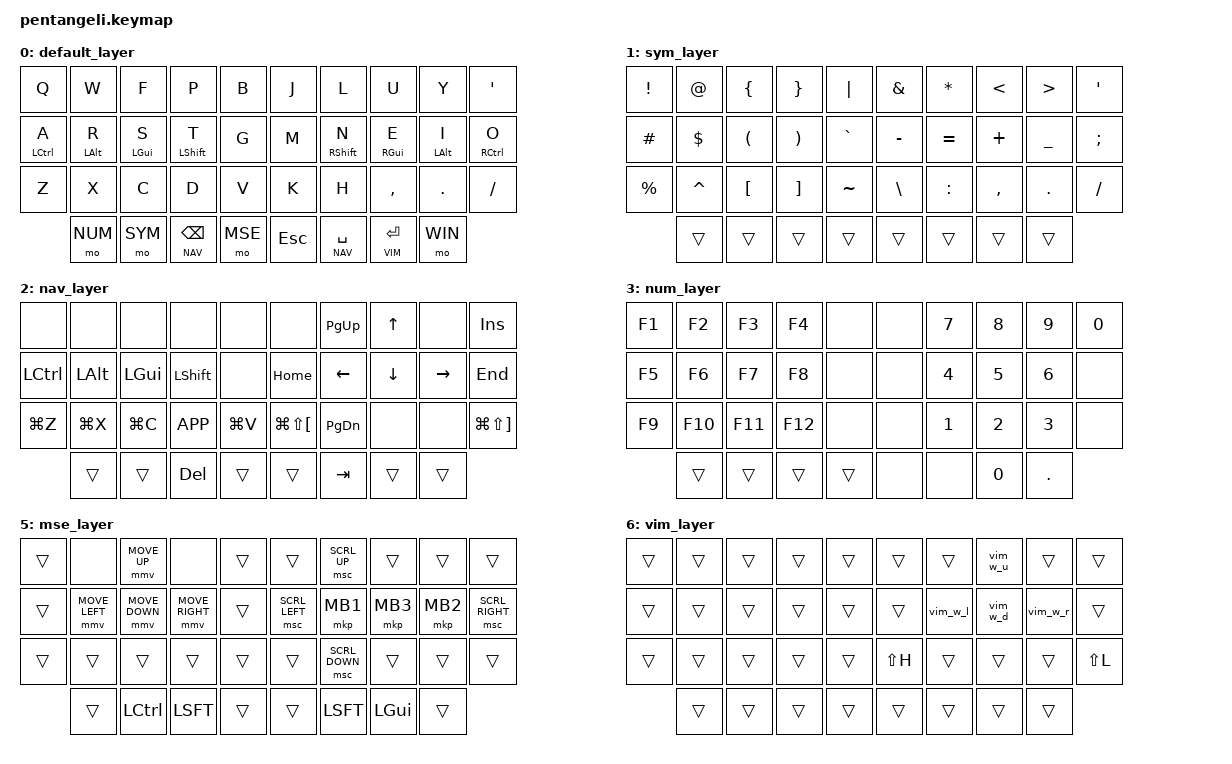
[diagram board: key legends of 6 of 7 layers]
#include <behaviors.dtsi>
#include <dt-bindings/zmk/keys.h>
#include <dt-bindings/zmk/bt.h>
#include <dt-bindings/zmk/mouse.h>
#include <dt-bindings/zmk/outputs.h>

#define DEFAULT 0
#define SYM     1
#define NAV     2
#define NUM     3
#define WIN     4
#define MSE     5
#define VIM     6

&lt {
  quick_tap_ms = <200>;
};

/ {

    behaviors {
        hm: homerow_mods {
            compatible = "zmk,behavior-hold-tap";
            label = "HOMEROW_MODS";
            #binding-cells = <2>;
            tapping-term-ms = <150>;
            quick-tap-ms = <200>;
            flavor = "tap-preferred";
            bindings = <&kp>, <&kp>;
        };
        hs: homerow_mods_slow {
            compatible = "zmk,behavior-hold-tap";
            label = "HOMEROW_MODS_SLOW";
            #binding-cells = <2>;
            tapping-term-ms = <200>;
            quick-tap-ms = <200>;
            flavor = "tap-preferred";
            bindings = <&kp>, <&kp>;
        };
        hf: homerow_mods_fast {
            compatible = "zmk,behavior-hold-tap";
            label = "HOMEROW_MODS_FAST";
            #binding-cells = <2>;
            tapping-term-ms = <110>;
            quick-tap-ms = <200>;
            flavor = "tap-preferred";
            bindings = <&kp>, <&kp>;
        };
    };

    macros {
        vim_w_l: vim_w_l {
            compatible = "zmk,behavior-macro";
            #binding-cells = <0>;
            bindings
                = <&macro_press &kp LCTRL>
                , <&macro_tap &kp W>
                , <&macro_release &kp LCTRL>
                , <&macro_tap &kp H>
                ;
        };
        vim_w_d: vim_w_d {
            compatible = "zmk,behavior-macro";
            #binding-cells = <0>;
            bindings
                = <&macro_press &kp LCTRL>
                , <&macro_tap &kp W>
                , <&macro_release &kp LCTRL>
                , <&macro_tap &kp J>
                ;
        };
        vim_w_u: vim_w_u {
            compatible = "zmk,behavior-macro";
            #binding-cells = <0>;
            bindings
                = <&macro_press &kp LCTRL>
                , <&macro_tap &kp W>
                , <&macro_release &kp LCTRL>
                , <&macro_tap &kp K>
                ;
        };
        vim_w_r: vim_w_r {
            compatible = "zmk,behavior-macro";
            #binding-cells = <0>;
            bindings
                = <&macro_press &kp LCTRL>
                , <&macro_tap &kp W>
                , <&macro_release &kp LCTRL>
                , <&macro_tap &kp L>
                ;
        };
    };

    combos {
        compatible = "zmk,combos";

        combo_capsword {
              timeout-ms = <50>;
              key-positions = <13 16>;
              bindings = <&caps_word>;
        };
    };

    keymap {
        compatible = "zmk,keymap";

        default_layer {
/* COLEMAK DH
 *
 * ,----------------------------------.                      ,----------------------------------.
 * |   Q  |   W  |   F  |   P  |   B  |                      |   J  |   L  |   U  |   Y  |   '  |
 * |------+------+------+------+------|                      |------+------+------+------+------|
 * |   A  |   R  |   S  |   T  |   G  |                      |   M  |   N  |   E  |   I  |   O  |
 * |------+------+------+------+------|                      |------+------+------+------+------|
 * |   Z  |   X  |   C  |   D  |   V  |                      |   K  |   H  |   ,  |   .  |   /  |
 * `----------------------------------'                      `----------------------------------'
 *            ,-----------------------.                      ,-----------------------.
 *            | NUM | SYM | NAV | MSE |                      | ESC | NAV | VIM | WIN |
 *            `-----------------------'                      `-----------------------'
 */
            bindings = <
    &kp Q       &kp W       &kp F       &kp P       &kp B           &kp J   &kp L       &kp U       &kp Y       &kp SQT
    &hm LCTRL A &hs LALT R  &hm LGUI S  &hf LSHFT T &kp G           &kp M   &hf RSHFT N &hm RGUI E  &hs LALT I  &hm RCTRL O
    &kp Z       &kp X       &kp C       &kp D       &kp V           &kp K   &kp H       &kp COMMA   &kp DOT     &kp FSLH
                &mo NUM     &mo SYM     &lt NAV BSPC &mo MSE        &kp ESC &lt NAV SPACE &lt VIM ENTER &mo WIN
            >;
        };

        sym_layer {
            bindings = <
    &kp EXCL    &kp AT    &kp LBRC &kp RBRC &kp PIPE        &kp AMPS  &kp ASTRK &kp LT    &kp GT    &kp SQT
    &kp HASH    &kp DLLR  &kp LPAR &kp RPAR &kp GRAVE       &kp MINUS &kp EQUAL &kp PLUS  &kp UNDER &kp SEMI
    &kp PRCNT   &kp CARET &kp LBKT &kp RBKT &kp TILDE       &kp BSLH  &kp COLON &kp COMMA &kp DOT   &kp FSLH
                &trans    &trans   &trans   &trans          &trans    &trans    &trans    &trans
          >;
      };

        nav_layer {
            bindings = <
    &none     &none     &none     &none     &none         &none           &kp PG_UP &kp UP   &none     &kp INS
    &kp LCTRL &kp LALT  &kp LGUI  &kp LSHFT &none         &kp HOME        &kp LEFT  &kp DOWN &kp RIGHT &kp END
    &kp LG(Z) &kp LG(X) &kp LG(C) &kp K_APP &kp LG(V)     &kp LG(LS(LBKT)) &kp PG_DN &none   &none     &kp LG(LS(RBKT))
              &trans    &trans    &kp DEL   &trans        &trans          &kp TAB   &trans   &trans
            >;
      };

        num_layer {
            bindings = <
    &kp F1    &kp F2    &kp F3    &kp F4    &none         &none     &kp N7    &kp N8    &kp N9    &kp N0
    &kp F5    &kp F6    &kp F7    &kp F8    &none         &none     &kp N4    &kp N5    &kp N6    &none
    &kp F9    &kp F10   &kp F11   &kp F12   &none         &none     &kp N1    &kp N2    &kp N3    &none
              &trans    &trans    &trans    &trans        &none     &none     &kp N0     &kp DOT
           >;
      };

        win_layer {
            bindings = <
    &bt BT_CLR &none &kp C_VOL_UP &none &bt BT_SEL 0              &none  &kp LG(EQUAL) &kp LC(LA(UP)) &kp LC(LA(EQUAL)) &none
    &out OUT_TOG  &kp C_PREV &kp C_PP &kp C_NEXT &bt BT_SEL 1     &kp LS(LG( N5)) &kp LC(LA(LEFT)) &kp LC(LA(DOWN)) &kp LC(LA(RIGHT)) &kp LC(LA(RET))
    &none &none &kp C_VOL_DN &kp C_MUTE &bt BT_SEL 2              &none &kp LG(MINUS) &none &kp LC(LA(MINUS)) &none &none
          &trans &trans &trans &bootloader                        &bootloader &trans &trans &trans
           >;
      };

        mse_layer {
            bindings = <
    &trans  &none          &mmv MOVE_UP   &none           &trans       &trans          &msc SCRL_UP    &trans    &trans   &trans
    &trans  &mmv MOVE_LEFT &mmv MOVE_DOWN &mmv MOVE_RIGHT &trans       &msc SCRL_LEFT  &mkp MB1        &mkp MB3  &mkp MB2 &msc SCRL_RIGHT
    &trans  &trans         &trans         &trans          &trans       &trans          &msc SCRL_DOWN  &trans    &trans   &trans
            &trans         &kp LCTL       &kp LSFT        &trans       &trans          &kp LSFT        &kp LGUI  &trans
            >;
      };
        vim_layer {
            bindings = <
    &trans  &trans         &trans         &trans          &trans       &trans          &trans        &vim_w_u  &trans     &trans
    &trans  &trans         &trans         &trans          &trans       &trans          &vim_w_l      &vim_w_d  &vim_w_r   &trans
    &trans  &trans         &trans         &trans          &trans       &kp LS(H)       &trans        &trans    &trans     &kp LS(L)
            &trans         &trans         &trans          &trans       &trans          &trans        &trans    &trans
            >;
      };
    };
};
